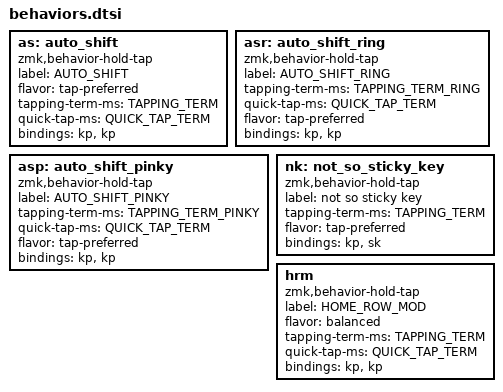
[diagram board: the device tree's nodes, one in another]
#define SK(KEY) &nk KEY KEY

#define RMODS (MOD_RGUI|MOD_RSFT|MOD_RALT|MOD_RCTL)
#define LMODS (MOD_LGUI|MOD_LSFT|MOD_LALT|MOD_LCTL)
#define ALLMODS (MOD_LGUI|MOD_LSFT|MOD_LALT|MOD_LCTL|MOD_RGUI|MOD_RSFT|MOD_RALT|MOD_RCTL)

as: auto_shift {
    compatible = "zmk,behavior-hold-tap";
    label = "AUTO_SHIFT";
    #binding-cells = <2>;
    flavor = "tap-preferred";
    tapping-term-ms = <TAPPING_TERM>;
    quick-tap-ms = <QUICK_TAP_TERM>;
    bindings = <&kp &kp>;
};

asr: auto_shift_ring {
    compatible = "zmk,behavior-hold-tap";
    label = "AUTO_SHIFT_RING";
    #binding-cells = <2>;
    tapping-term-ms = <TAPPING_TERM_RING>;
    quick-tap-ms = <QUICK_TAP_TERM>;
    flavor = "tap-preferred";
    bindings = <&kp &kp>;
};

asp: auto_shift_pinky {
    compatible = "zmk,behavior-hold-tap";
    label = "AUTO_SHIFT_PINKY";
    #binding-cells = <2>;
    tapping-term-ms = <TAPPING_TERM_PINKY>;
    quick-tap-ms = <QUICK_TAP_TERM>;
    flavor = "tap-preferred";
    bindings = <&kp &kp>;
};

nk: not_so_sticky_key {
    compatible = "zmk,behavior-hold-tap";
    label = "not so sticky key";
    #binding-cells = <2>;
    tapping-term-ms = <TAPPING_TERM>;
    flavor = "tap-preferred";
    bindings = <&kp &sk>;
};

hrm: hrm {
    compatible = "zmk,behavior-hold-tap";
    label = "HOME_ROW_MOD";
    #binding-cells = <2>;
    flavor = "balanced";
    tapping-term-ms = <TAPPING_TERM>;
    quick-tap-ms = <QUICK_TAP_TERM>;
    bindings = <&kp &kp>;
};

